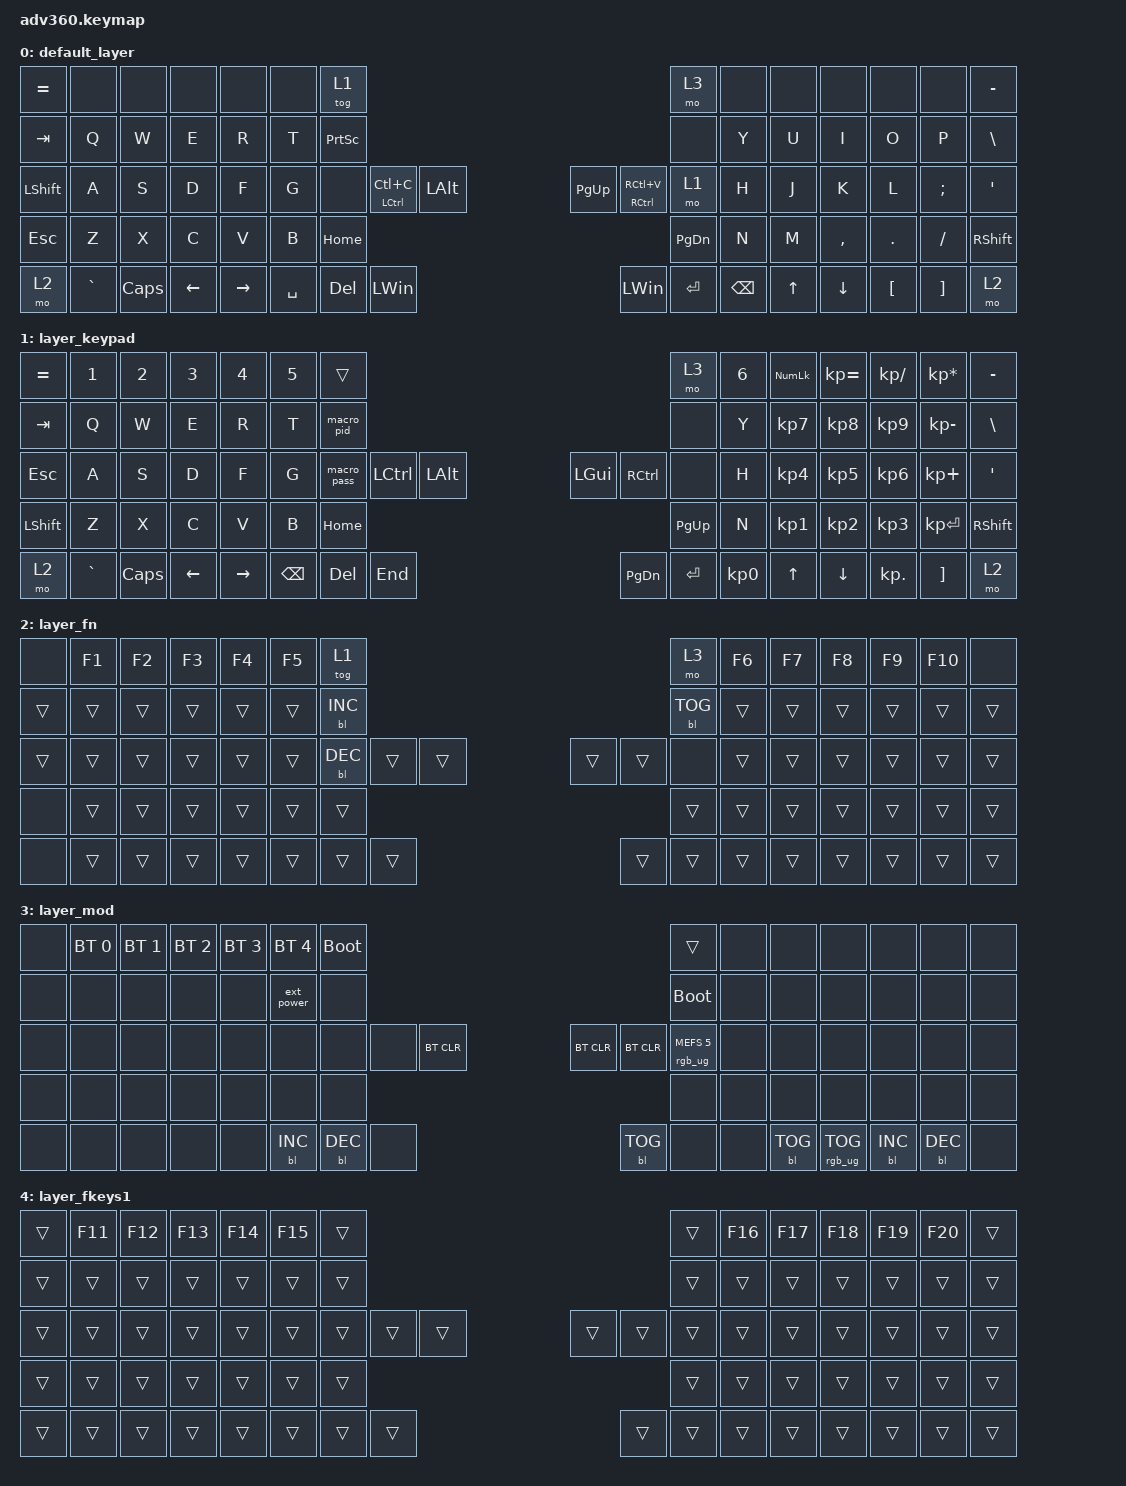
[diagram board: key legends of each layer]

/*
 * Copyright (c) 2020 The ZMK Contributors
 *
 * SPDX-License-Identifier: MIT
 */


/* THIS FILE WAS GENERATED!
 *
 * This file was generated automatically. You may or may not want to
 * edit it directly.
 */

#include <behaviors.dtsi>
#include <dt-bindings/zmk/keys.h>
#include <dt-bindings/zmk/backlight.h>
#include <dt-bindings/zmk/bt.h>
#include <dt-bindings/zmk/ext_power.h>
#include <dt-bindings/zmk/rgb.h>

/ {
  behaviors {
    #include "macros.dtsi"

    hm: homerow_mods {
        compatible = "zmk,behavior-hold-tap";
        label = "HOMEROW_MODS";
        #binding-cells = <2>;
        tapping-term-ms = <200>;
        quick_tap_ms = <175>;
        flavor = "tap-preferred";
        bindings = <&kp>, <&kp>;
    };
  };

    keymap {
        compatible = "zmk,keymap";


        default_layer {
            bindings = <
      &kp EQUAL      &none     &none     &none      &none   &none                     &tog 1                                                                                                &mo 3   &none   &none      &none     &none     &none  &kp MINUS
        &kp TAB      &kp Q     &kp W     &kp E      &kp R   &kp T            &kp PRINTSCREEN                                                                                                &none   &kp Y   &kp U      &kp I     &kp O     &kp P   &kp BSLH
 &kp LEFT_SHIFT      &kp A     &kp S     &kp D      &kp F   &kp G                      &none  &mt LEFT_CONTROL LC(C)      &kp LALT                      &kp PG_UP  &mt RCTRL RC(V)          &mo 1   &kp H   &kp J      &kp K     &kp L  &kp SEMI    &kp SQT
        &kp ESC      &kp Z     &kp X     &kp C      &kp V   &kp B                                                         &kp HOME                  &kp PAGE_DOWN                                   &kp N   &kp M  &kp COMMA   &kp DOT  &kp FSLH  &kp RSHFT
          &mo 2  &kp GRAVE  &kp CAPS  &kp LEFT  &kp RIGHT                          &kp SPACE                 &kp DEL  &kp LEFT_WIN                   &kp LEFT_WIN        &kp ENTER  &kp BACKSPACE          &kp UP   &kp DOWN  &kp LBKT  &kp RBKT      &mo 2
            >;
        };

        layer_keypad {
            bindings = <
 &kp EQUAL     &kp N1    &kp N2    &kp N3     &kp N4  &kp N5                 &trans                                                                 &mo 3  &kp N6  &kp KP_NUM  &kp KP_EQUAL  &kp KP_DIVIDE  &kp KP_MULTIPLY  &kp MINUS
   &kp TAB      &kp Q     &kp W     &kp E      &kp R   &kp T             &macro_pid                                                                 &none   &kp Y   &kp KP_N7     &kp KP_N8      &kp KP_N9     &kp KP_MINUS   &kp BSLH
   &kp ESC      &kp A     &kp S     &kp D      &kp F   &kp G            &macro_pass  &kp LCTRL  &kp LALT                   &kp LGUI  &kp RCTRL      &none   &kp H   &kp KP_N4     &kp KP_N5      &kp KP_N6      &kp KP_PLUS    &kp SQT
 &kp LSHFT      &kp Z     &kp X     &kp C      &kp V   &kp B                                    &kp HOME                  &kp PG_UP                         &kp N   &kp KP_N1     &kp KP_N2      &kp KP_N3     &kp KP_ENTER  &kp RSHFT
     &mo 2  &kp GRAVE  &kp CAPS  &kp LEFT  &kp RIGHT                       &kp BSPC    &kp DEL   &kp END                  &kp PG_DN  &kp ENTER  &kp KP_N0              &kp UP      &kp DOWN     &kp KP_DOT         &kp RBKT      &mo 2
            >;
        };

        layer_fn {
            bindings = <
  &none  &kp F1  &kp F2  &kp F3  &kp F4  &kp F5                &tog 1                                                       &mo 3  &kp F6  &kp F7  &kp F8  &kp F9  &kp F10   &none
 &trans  &trans  &trans  &trans  &trans  &trans            &bl BL_INC                                                  &bl BL_TOG  &trans  &trans  &trans  &trans   &trans  &trans
 &trans  &trans  &trans  &trans  &trans  &trans            &bl BL_DEC  &trans  &trans                  &trans  &trans       &none  &trans  &trans  &trans  &trans   &trans  &trans
  &none  &trans  &trans  &trans  &trans  &trans                                &trans                  &trans                      &trans  &trans  &trans  &trans   &trans  &trans
  &none  &trans  &trans  &trans  &trans                        &trans  &trans  &trans                  &trans  &trans      &trans          &trans  &trans  &trans   &trans  &trans
            >;
        };

        layer_mod {
            bindings = <
  &none  &bt BT_SEL 0  &bt BT_SEL 1  &bt BT_SEL 2  &bt BT_SEL 3  &bt BT_SEL 4            &bootloader                                                                                  &trans   &none       &none            &none       &none       &none   &none
  &none         &none         &none         &none         &none    &ext_power                  &none                                                                             &bootloader   &none       &none            &none       &none       &none   &none
  &none         &none         &none         &none         &none         &none                  &none       &none  &bt BT_CLR                  &bt BT_CLR  &bt BT_CLR  &rgb_ug RGB_MEFS_CMD 5   &none       &none            &none       &none       &none   &none
  &none         &none         &none         &none         &none         &none                                          &none                       &none                                       &none       &none            &none       &none       &none   &none
  &none         &none         &none         &none         &none                           &bl BL_INC  &bl BL_DEC       &none                  &bl BL_TOG       &none                   &none          &bl BL_TOG  &rgb_ug RGB_TOG  &bl BL_INC  &bl BL_DEC   &none
            >;
        };

        layer_fkeys1 {
            bindings = <
 &trans  &kp F11  &kp F12  &kp F13  &kp F14  &kp F15            &trans                                                  &trans  &kp F16  &kp F17  &kp F18  &kp F19  &kp F20  &trans
 &trans   &trans   &trans   &trans   &trans   &trans            &trans                                                  &trans   &trans   &trans   &trans   &trans   &trans  &trans
 &trans   &trans   &trans   &trans   &trans   &trans            &trans  &trans  &trans                  &trans  &trans  &trans   &trans   &trans   &trans   &trans   &trans  &trans
 &trans   &trans   &trans   &trans   &trans   &trans                            &trans                  &trans                   &trans   &trans   &trans   &trans   &trans  &trans
 &trans   &trans   &trans   &trans   &trans                     &trans  &trans  &trans                  &trans  &trans  &trans            &trans   &trans   &trans   &trans  &trans
            >;
        };

    };
};
